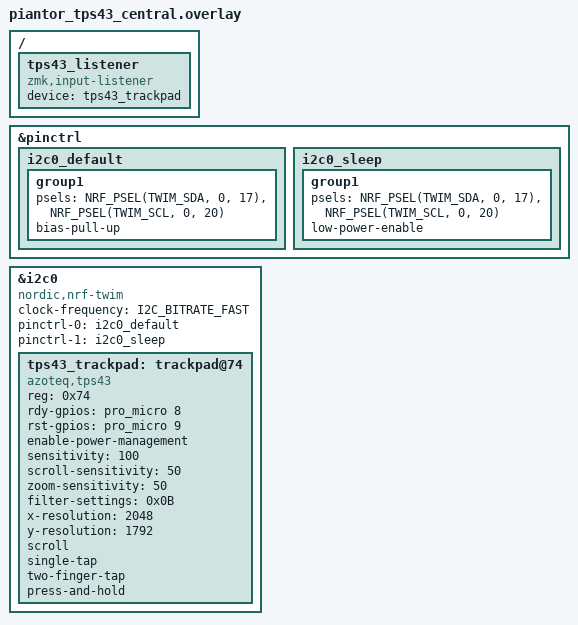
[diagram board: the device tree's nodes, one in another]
#include <dt-bindings/zmk/input_transform.h>
#include <zephyr/dt-bindings/pinctrl/nrf-pinctrl.h>

&pinctrl {
    i2c0_default: i2c0_default {
        group1 {
            psels = <NRF_PSEL(TWIM_SDA, 0, 17)>, /* U1.5 / P0.17 -> J_TPS.6 SDA */
                    <NRF_PSEL(TWIM_SCL, 0, 20)>; /* U1.6 / P0.20 -> J_TPS.5 SCL */
            bias-pull-up;
        };
    };

    i2c0_sleep: i2c0_sleep {
        group1 {
            psels = <NRF_PSEL(TWIM_SDA, 0, 17)>,
                    <NRF_PSEL(TWIM_SCL, 0, 20)>;
            low-power-enable;
        };
    };
};

&i2c0 {
    compatible = "nordic,nrf-twim";
    status = "okay";
    clock-frequency = <I2C_BITRATE_FAST>;
    pinctrl-0 = <&i2c0_default>;
    pinctrl-1 = <&i2c0_sleep>;
    pinctrl-names = "default", "sleep";

    tps43_trackpad: trackpad@74 {
        compatible = "azoteq,tps43";
        reg = <0x74>;
        status = "okay";

        /* J_TPS.1 (RDY) -> U1.11 / P1.04 (&pro_micro 8), J_TPS.2 (NRST) -> U1.12 / P1.06 (&pro_micro 9) */
        rdy-gpios = <&pro_micro 8 GPIO_ACTIVE_HIGH>;
        rst-gpios = <&pro_micro 9 GPIO_ACTIVE_HIGH>;

        enable-power-management;
        sensitivity = <100>;
        scroll-sensitivity = <50>;
        zoom-sensitivity = <50>;
        filter-settings = <0x0B>;
        x-resolution = <2048>;
        y-resolution = <1792>;

        scroll;
        single-tap;
        two-finger-tap;
        press-and-hold;
        /* 如触摸方向与安装方向不一致，可取消注释以下任意属性微调：
         * switch-xy;
         * invert-x;
         * invert-y;
         * invert-scroll-y;
         */
    };
};

/ {
    tps43_listener: tps43_listener {
        compatible = "zmk,input-listener";
        device = <&tps43_trackpad>;
        status = "okay";
    };
};
